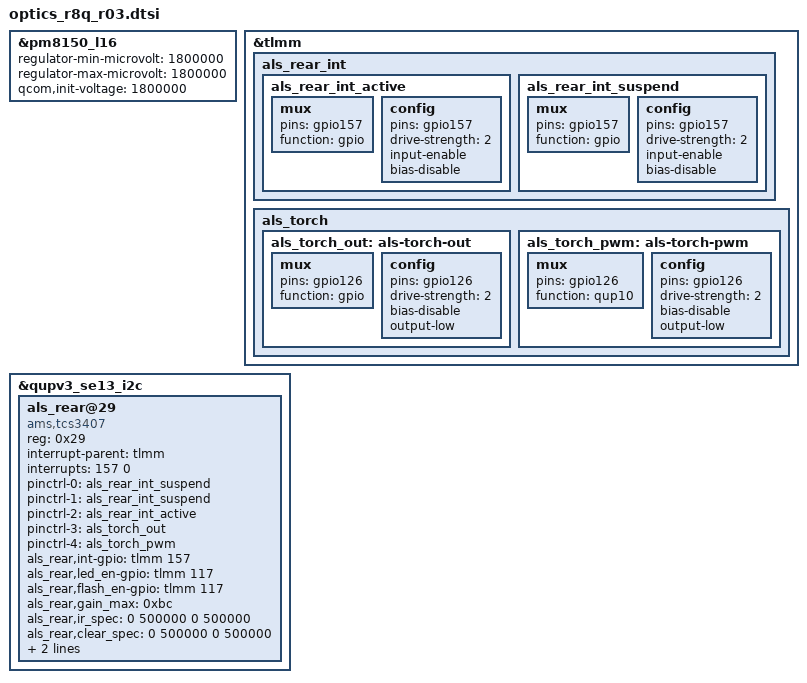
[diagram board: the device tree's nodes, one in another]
/*
 * Copyright (c) 2020, The Linux Foundation. All rights reserved.
 *
 * This program is free software; you can redistribute it and/or modify
 * it under the terms of the GNU General Public License version 2 and
 * only version 2 as published by the Free Software Foundation.
 *
 * This program is distributed in the hope that it will be useful,
 * but WITHOUT ANY WARRANTY; without even the implied warranty of
 * MERCHANTABILITY or FITNESS FOR A PARTICULAR PURPOSE.  See the
 * GNU General Public License for more details.
 */

&pm8150_l16 {
	regulator-min-microvolt = <1800000>;
	regulator-max-microvolt = <1800000>;
	qcom,init-voltage = <1800000>;
};

&tlmm {
	als_rear_int {
		als_rear_int_active: als_rear_int_active {
			mux {
				pins = "gpio157";
				function = "gpio";
			};

			config {
				pins = "gpio157";
				drive-strength = <2>;
				input-enable;
				bias-disable;
			};
		};
		als_rear_int_suspend: als_rear_int_suspend {
			mux {
				pins = "gpio157";
				function = "gpio";
			};

			config {
				pins = "gpio157";
				drive-strength = <2>;
				input-enable;
				bias-disable;
			};
		};
	};

	als_torch {
		als_torch_out: als-torch-out {
			mux {
				pins = "gpio126";
				function = "gpio";
			};

			config {
				pins = "gpio126";
				drive-strength = <2>;   /* 16 mA */
				bias-disable;
				output-low;

			};
		};

		als_torch_pwm: als-torch-pwm {
			mux {
				pins = "gpio126";
				function = "qup10";
			};

			config {
				pins = "gpio126";
				drive-strength = <2>;   /* 16 mA */
				bias-disable;
				output-low;
			};
		};
	};
};

&qupv3_se13_i2c {
	status = "ok";
	als_rear@29 {
		compatible = "ams,tcs3407";
		reg = <0x29>;
		interrupt-parent = <&tlmm>;
		interrupts = <157 0>;
		pinctrl-names = "sleep", "default", "idle", "torch_out", "torch_pwm";
		pinctrl-0 = <&als_rear_int_suspend>;
		pinctrl-1 = <&als_rear_int_suspend>;
		pinctrl-2 = <&als_rear_int_active>;
		pinctrl-3 = <&als_torch_out>;
		pinctrl-4 = <&als_torch_pwm>;
/*
		clocks = <&clock_gcc GCC_GP1_CLK_SRC>, <&clock_gcc GCC_GP1_CLK >;
		clock-names = "gpio_pwm_default-clk", "gpio_pwm_default-clk-cbcr";
*/
		als_rear,int-gpio = <&tlmm 157 0x00>;
/*		als_rear,als_en-gpio = <&pm8150_l16>;	*/
		als_rear,led_en-gpio = <&tlmm 117 0x00>;    /* CAM_TORCH_EN */
		als_rear,flash_en-gpio = <&tlmm 117 0x00>;  /* CAM_FLASH_EN */
		als_rear,gain_max = <0xbc>;
		als_rear,ir_spec = <0 500000 0 500000>;
		als_rear,clear_spec = <0 500000 0 500000>;
		als_rear,icratio_spec = <0 10000 0 10000>;

		vdd_1p8-supply = <&pm8150_l16>;
/*
		als_rear,i2c_1p8 = <&pm8150_l16>;
*/
	};
};
